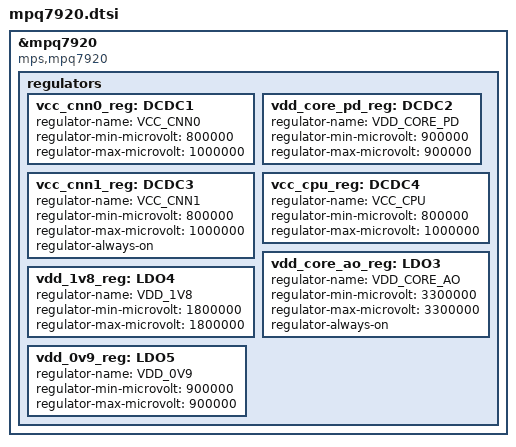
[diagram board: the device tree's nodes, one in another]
&mpq7920 {
	compatible = "mps,mpq7920";
	regulators {
		vcc_cnn0_reg: DCDC1 {
			regulator-name = "VCC_CNN0";
			regulator-min-microvolt = <800000>;
			regulator-max-microvolt = <1000000>;
	     	};

		vdd_core_pd_reg: DCDC2 {
		     	regulator-name = "VDD_CORE_PD";
		     	regulator-min-microvolt = <900000>;
		     	regulator-max-microvolt = <900000>;
	     	};

		vcc_cnn1_reg: DCDC3 {
		     	regulator-name = "VCC_CNN1";
		     	regulator-min-microvolt = <800000>;
		     	regulator-max-microvolt = <1000000>;
		     	regulator-always-on;
	     	};

		vcc_cpu_reg: DCDC4 {
		     	regulator-name = "VCC_CPU";
		     	regulator-min-microvolt = <800000>;
		     	regulator-max-microvolt = <1000000>;
	     	};

		vdd_core_ao_reg: LDO3 {
			regulator-name = "VDD_CORE_AO";
		     	regulator-min-microvolt = <3300000>;
		     	regulator-max-microvolt = <3300000>;
		    	regulator-always-on;
	     	};

		vdd_1v8_reg: LDO4 {
		    	regulator-name = "VDD_1V8";
		    	regulator-min-microvolt = <1800000>;
		    	regulator-max-microvolt = <1800000>;
	    	};

		vdd_0v9_reg: LDO5 {
		  	regulator-name = "VDD_0V9";
		  	regulator-min-microvolt = <900000>;
		  	regulator-max-microvolt = <900000>;
	  	};
      };
};

